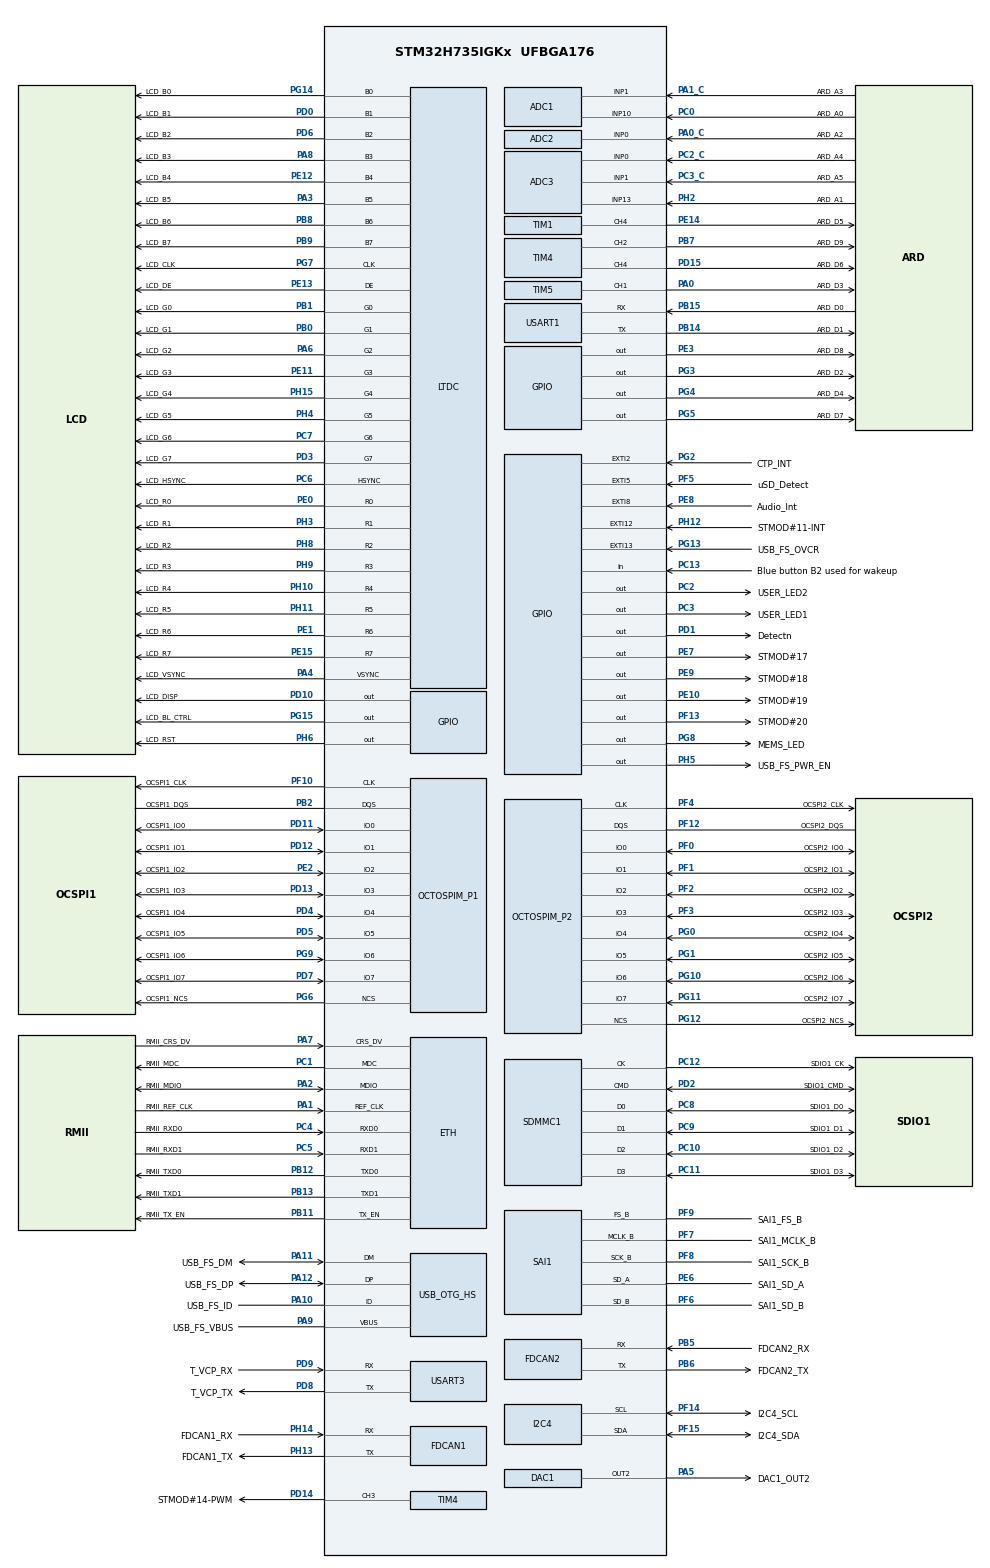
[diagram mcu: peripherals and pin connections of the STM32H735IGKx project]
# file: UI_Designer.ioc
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ADC1.Channel-1\#ChannelRegularConversion=ADC_CHANNEL_1
ADC1.NbrOfConversionFlag=1
ADC1.OffsetNumber-1\#ChannelRegularConversion=ADC_OFFSET_NONE
ADC1.OffsetSignedSaturation-1\#ChannelRegularConversion=DISABLE
ADC1.Rank-1\#ChannelRegularConversion=1
ADC1.SamplingTime-1\#ChannelRegularConversion=ADC_SAMPLETIME_1CYCLE_5
ADC1.master=1
ADC2.Channel-0\#ChannelRegularConversion=ADC_CHANNEL_0
ADC2.NbrOfConversionFlag=1
ADC2.OffsetNumber-0\#ChannelRegularConversion=ADC_OFFSET_NONE
ADC2.OffsetSignedSaturation-0\#ChannelRegularConversion=DISABLE
ADC2.Rank-0\#ChannelRegularConversion=1
ADC2.SamplingTime-0\#ChannelRegularConversion=ADC_SAMPLETIME_1CYCLE_5
ADC3.Channel-2\#ChannelRegularConversion=ADC_CHANNEL_0
ADC3.NbrOfConversionFlag=1
ADC3.OffsetNumber-2\#ChannelRegularConversion=ADC_OFFSET_NONE
ADC3.OffsetSaturation-2\#ChannelRegularConversion=DISABLE
ADC3.OffsetSign-2\#ChannelRegularConversion=ADC3_OFFSET_SIGN_NEGATIVE
ADC3.OffsetSignedSaturation-2\#ChannelRegularConversion=DISABLE
ADC3.Rank-2\#ChannelRegularConversion=1
ADC3.SamplingTime-2\#ChannelRegularConversion=ADC3_SAMPLETIME_2CYCLES_5
DAC1.DAC_Channel-DAC_OUT2=DAC_CHANNEL_2
ETH.MediaInterface=HAL_ETH_RMII_MODE
FDCAN1.CalculateBaudRateNominal=2864583
FDCAN1.CalculateTimeBitNominal=349
FDCAN1.CalculateTimeQuantumNominal=116.36363636363636
FDCAN2.CalculateBaudRateNominal=2864583
FDCAN2.CalculateTimeBitNominal=349
FDCAN2.CalculateTimeQuantumNominal=116.36363636363636
I2C4.Timing=0x60404E72
Mcu.Family=STM32H7
Mcu.Name=STM32H735IGKx
Mcu.Package=UFBGA176
NVIC.PriorityGroup=NVIC_PRIORITYGROUP_4
PA0.GPIO_Label=ARD_D3
PA0.Signal=S_TIM5_CH1
PA0_C.GPIO_Label=ARD_A2
PA0_C.Signal=ADCx_INP0
PA1.GPIO_Label=RMII_REF_CLK
PA1.GPIO_Speed=GPIO_SPEED_FREQ_LOW
PA1.Mode=RMII
PA1.Signal=ETH_REF_CLK
PA10.GPIO_Label=USB_FS_ID
PA10.Mode=OTG/Dual-Role-Device-FS
PA10.Signal=USB_OTG_HS_ID
PA11.GPIO_Label=USB_FS_DM
PA11.Mode=OTG/Dual-Role-Device-FS
PA11.Signal=USB_OTG_HS_DM
PA12.GPIO_Label=USB_FS_DP
PA12.Mode=OTG/Dual-Role-Device-FS
PA12.Signal=USB_OTG_HS_DP
PA13(JTMS/SWDIO).GPIO_Label=JTMS
PA13(JTMS/SWDIO).Mode=Trace_Asynchronous_SW
PA13(JTMS/SWDIO).Signal=DEBUG_JTMS-SWDIO
PA14(JTCK/SWCLK).GPIO_Label=JTCK
PA14(JTCK/SWCLK).Mode=Trace_Asynchronous_SW
PA14(JTCK/SWCLK).Signal=DEBUG_JTCK-SWCLK
PA15(JTDI).GPIO_Label=JTDI
PA15(JTDI).Signal=DEBUG_JTDI
PA1_C.GPIO_Label=ARD_A3
PA1_C.Signal=ADCx_INP1
PA2.GPIO_Label=RMII_MDIO
PA2.GPIO_Speed=GPIO_SPEED_FREQ_LOW
PA2.Mode=RMII
PA2.Signal=ETH_MDIO
PA3.GPIO_Label=LCD_B5
PA3.GPIO_Speed=GPIO_SPEED_FREQ_LOW
PA3.Mode=RGB888
PA3.Signal=LTDC_B5
PA4.GPIO_Label=LCD_VSYNC
PA4.GPIO_Speed=GPIO_SPEED_FREQ_LOW
PA4.Mode=RGB888
PA4.Signal=LTDC_VSYNC
PA5.GPIO_Label=DAC1_OUT2
PA5.Signal=COMP_DAC12_group
PA6.GPIO_Label=LCD_G2
PA6.GPIO_Speed=GPIO_SPEED_FREQ_LOW
PA6.Mode=RGB888
PA6.Signal=LTDC_G2
PA7.GPIO_Label=RMII_CRS_DV
PA7.GPIO_Speed=GPIO_SPEED_FREQ_LOW
PA7.Mode=RMII
PA7.Signal=ETH_CRS_DV
PA8.GPIO_Label=LCD_B3
PA8.GPIO_Speed=GPIO_SPEED_FREQ_LOW
PA8.Mode=RGB888
PA8.Signal=LTDC_B3
PA9.GPIO_Label=USB_FS_VBUS
PA9.Mode=Activate_VBUS_FS
PA9.Signal=USB_OTG_HS_VBUS
PB0.GPIO_Label=LCD_G1
PB0.GPIO_Speed=GPIO_SPEED_FREQ_LOW
PB0.Mode=RGB888
PB0.Signal=LTDC_G1
PB1.GPIO_Label=LCD_G0
PB1.GPIO_Speed=GPIO_SPEED_FREQ_LOW
PB1.Mode=RGB888
PB1.Signal=LTDC_G0
PB10.GPIO_Label=RMII_RX_ER
PB10.Signal=ETH_RX_ER
PB11.GPIO_Label=RMII_TX_EN
PB11.GPIO_Speed=GPIO_SPEED_FREQ_LOW
PB11.Mode=RMII
PB11.Signal=ETH_TX_EN
PB12.GPIO_Label=RMII_TXD0
PB12.GPIO_Speed=GPIO_SPEED_FREQ_LOW
PB12.Mode=RMII
PB12.Signal=ETH_TXD0
PB13.GPIO_Label=RMII_TXD1
PB13.GPIO_Speed=GPIO_SPEED_FREQ_LOW
PB13.Mode=RMII
PB13.Signal=ETH_TXD1
PB14.GPIO_Label=ARD_D1
PB14.GPIO_PuPd=GPIO_NOPULL
PB14.Mode=Asynchronous
PB14.Signal=USART1_TX
PB15.GPIO_Label=ARD_D0
PB15.GPIO_PuPd=GPIO_NOPULL
PB15.Mode=Asynchronous
PB15.Signal=USART1_RX
PB2.GPIO_Label=OCSPI1_DQS
PB2.Mode=OCTOSPI1_Port1_DQS
PB2.Signal=OCTOSPIM_P1_DQS
PB3(JTDO/TRACESWO).GPIO_Label=JTDO
PB3(JTDO/TRACESWO).Mode=Trace_Asynchronous_SW
PB3(JTDO/TRACESWO).Signal=DEBUG_JTDO-SWO
PB4(NJTRST).GPIO_Label=NJTRST
PB4(NJTRST).Signal=DEBUG_JTRST
PB5.GPIO_Label=FDCAN2_RX
PB5.Mode=FDCAN_Activate
PB5.Signal=FDCAN2_RX
PB6.GPIO_Label=FDCAN2_TX
PB6.Mode=FDCAN_Activate
PB6.Signal=FDCAN2_TX
PB7.GPIO_Label=ARD_D9
PB7.Signal=S_TIM4_CH2
PB8.GPIO_Label=LCD_B6
PB8.GPIO_Speed=GPIO_SPEED_FREQ_LOW
PB8.Mode=RGB888
PB8.Signal=LTDC_B6
PB9.GPIO_Label=LCD_B7
PB9.GPIO_Speed=GPIO_SPEED_FREQ_LOW
PB9.Mode=RGB888
PB9.Signal=LTDC_B7
PC0.GPIO_Label=ARD_A0
PC0.Signal=ADCx_INP10
PC1.GPIO_Label=RMII_MDC
PC1.GPIO_Speed=GPIO_SPEED_FREQ_LOW
PC1.Mode=RMII
PC1.Signal=ETH_MDC
PC10.GPIO_Label=SDIO1_D2
PC10.Mode=SD_4_bits_Wide_bus
PC10.Signal=SDMMC1_D2
PC11.GPIO_Label=SDIO1_D3
PC11.Mode=SD_4_bits_Wide_bus
PC11.Signal=SDMMC1_D3
PC12.GPIO_Label=SDIO1_CK
PC12.Mode=SD_4_bits_Wide_bus
PC12.Signal=SDMMC1_CK
PC13.GPIO_Label=Blue button B2 used for wakeup
PC13.Signal=GPIO_Input
PC14-OSC32_IN.Mode=LSE-External-Oscillator
PC14-OSC32_IN.Signal=RCC_OSC32_IN
PC15-OSC32_OUT.Mode=LSE-External-Oscillator
PC15-OSC32_OUT.Signal=RCC_OSC32_OUT
PC2.GPIO_Label=USER_LED2
PC2.Signal=GPIO_Output
PC2_C.GPIO_Label=ARD_A4
PC2_C.Mode=IN0-Single-Ended
PC2_C.Signal=ADC3_INP0
PC3.GPIO_Label=USER_LED1
PC3.Signal=GPIO_Output
PC3_C.GPIO_Label=ARD_A5
PC3_C.Mode=IN1-Single-Ended
PC3_C.Signal=ADC3_INP1
PC4.GPIO_Label=RMII_RXD0
PC4.GPIO_Speed=GPIO_SPEED_FREQ_LOW
PC4.Mode=RMII
PC4.Signal=ETH_RXD0
PC5.GPIO_Label=RMII_RXD1
PC5.GPIO_Speed=GPIO_SPEED_FREQ_LOW
PC5.Mode=RMII
PC5.Signal=ETH_RXD1
PC6.GPIO_Label=LCD_HSYNC
PC6.GPIO_Speed=GPIO_SPEED_FREQ_LOW
PC6.Mode=RGB888
PC6.Signal=LTDC_HSYNC
PC7.GPIO_Label=LCD_G6
PC7.GPIO_Speed=GPIO_SPEED_FREQ_LOW
PC7.Mode=RGB888
PC7.Signal=LTDC_G6
PC8.GPIO_Label=SDIO1_D0
PC8.Mode=SD_4_bits_Wide_bus
PC8.Signal=SDMMC1_D0
PC9.GPIO_Label=SDIO1_D1
PC9.Mode=SD_4_bits_Wide_bus
PC9.Signal=SDMMC1_D1
PD0.GPIO_Label=LCD_B1
PD0.GPIO_Speed=GPIO_SPEED_FREQ_LOW
PD0.Mode=RGB888
PD0.Signal=LTDC_B1
PD1.GPIO_Label=Detectn
PD1.GPIO_PuPd=GPIO_NOPULL
PD1.Signal=GPIO_Output
PD10.GPIO_Label=LCD_DISP
PD10.GPIO_Speed=GPIO_SPEED_FREQ_LOW
PD10.Signal=GPIO_Output
PD11.GPIO_Label=OCSPI1_IO0
PD11.Mode=OCTOSPI1_IOL_Port1L
PD11.Signal=OCTOSPIM_P1_IO0
PD12.GPIO_Label=OCSPI1_IO1
PD12.Mode=OCTOSPI1_IOL_Port1L
PD12.Signal=OCTOSPIM_P1_IO1
PD13.GPIO_Label=OCSPI1_IO3
PD13.Mode=OCTOSPI1_IOL_Port1L
PD13.Signal=OCTOSPIM_P1_IO3
PD14.GPIO_Label=STMOD\#14-PWM
PD14.Signal=S_TIM4_CH3
PD15.GPIO_Label=ARD_D6
PD15.Signal=S_TIM4_CH4
PD2.GPIO_Label=SDIO1_CMD
PD2.Mode=SD_4_bits_Wide_bus
PD2.Signal=SDMMC1_CMD
PD3.GPIO_Label=LCD_G7
PD3.GPIO_Speed=GPIO_SPEED_FREQ_LOW
PD3.Mode=RGB888
PD3.Signal=LTDC_G7
PD4.GPIO_Label=OCSPI1_IO4
PD4.Mode=OCTOSPI1_IOH_Port1H
PD4.Signal=OCTOSPIM_P1_IO4
PD5.GPIO_Label=OCSPI1_IO5
PD5.Mode=OCTOSPI1_IOH_Port1H
PD5.Signal=OCTOSPIM_P1_IO5
PD6.GPIO_Label=LCD_B2
PD6.GPIO_Speed=GPIO_SPEED_FREQ_LOW
PD6.Mode=RGB888
PD6.Signal=LTDC_B2
PD7.GPIO_Label=OCSPI1_IO7
PD7.Mode=OCTOSPI1_IOH_Port1H
PD7.Signal=OCTOSPIM_P1_IO7
PD8.GPIO_Label=T_VCP_TX
PD8.GPIO_PuPd=GPIO_NOPULL
PD8.Mode=Asynchronous
PD8.Signal=USART3_TX
PD9.GPIO_Label=T_VCP_RX
PD9.GPIO_PuPd=GPIO_NOPULL
PD9.Mode=Asynchronous
PD9.Signal=USART3_RX
PE0.GPIO_Label=LCD_R0
PE0.GPIO_Speed=GPIO_SPEED_FREQ_LOW
PE0.Mode=RGB888
PE0.Signal=LTDC_R0
PE1.GPIO_Label=LCD_R6
PE1.GPIO_Speed=GPIO_SPEED_FREQ_LOW
PE1.Mode=RGB888
PE1.Signal=LTDC_R6
PE10.GPIO_Label=STMOD\#19
PE10.Signal=GPIO_Output
PE11.GPIO_Label=LCD_G3
PE11.GPIO_Speed=GPIO_SPEED_FREQ_LOW
PE11.Mode=RGB888
PE11.Signal=LTDC_G3
PE12.GPIO_Label=LCD_B4
PE12.GPIO_Speed=GPIO_SPEED_FREQ_LOW
PE12.Mode=RGB888
PE12.Signal=LTDC_B4
PE13.GPIO_Label=LCD_DE
PE13.GPIO_Speed=GPIO_SPEED_FREQ_LOW
PE13.Mode=RGB888
PE13.Signal=LTDC_DE
PE14.GPIO_Label=ARD_D5
PE14.Signal=S_TIM1_CH4
PE15.GPIO_Label=LCD_R7
PE15.GPIO_Speed=GPIO_SPEED_FREQ_LOW
PE15.Mode=RGB888
PE15.Signal=LTDC_R7
PE2.GPIO_Label=OCSPI1_IO2
PE2.Mode=OCTOSPI1_IOL_Port1L
PE2.Signal=OCTOSPIM_P1_IO2
PE3.GPIO_Label=ARD_D8
PE3.Signal=GPIO_Output
PE4.GPIO_Label=SAI4_D2
PE4.Signal=SAI4_D2
PE5.GPIO_Label=SAI4_CK2
PE5.Signal=SAI4_CK2
PE6.GPIO_Label=SAI1_SD_A
PE6.Mode=SAI_A_SyncSlave
PE6.Signal=SAI1_SD_A
PE7.GPIO_Label=STMOD\#17
PE7.Signal=GPIO_Output
PE8.GPIO_Label=Audio_Int
PE8.Signal=GPXTI8
PE9.GPIO_Label=STMOD\#18
PE9.Signal=GPIO_Output
PF0.GPIO_Label=OCSPI2_IO0
PF0.Mode=OCTOSPI2_IOL_Port2L
PF0.Signal=OCTOSPIM_P2_IO0
PF1.GPIO_Label=OCSPI2_IO1
PF1.Mode=OCTOSPI2_IOL_Port2L
PF1.Signal=OCTOSPIM_P2_IO1
PF10.GPIO_Label=OCSPI1_CLK
PF10.Mode=O1_P1_CLK
PF10.Signal=OCTOSPIM_P1_CLK
PF11.GPIO_Label=SPI5_MOSI
PF11.Signal=SPI5_MOSI
PF12.GPIO_Label=OCSPI2_DQS
PF12.Mode=OCTOSPI2_Port2_DQS
PF12.Signal=OCTOSPIM_P2_DQS
PF13.GPIO_Label=STMOD\#20
PF13.Signal=GPIO_Output
PF14.GPIO_Label=I2C4_SCL
PF14.GPIO_Pu=GPIO_PULLUP
PF14.Mode=I2C
PF14.Signal=I2C4_SCL
PF15.GPIO_Label=I2C4_SDA
PF15.GPIO_Pu=GPIO_PULLUP
PF15.Mode=I2C
PF15.Signal=I2C4_SDA
PF2.GPIO_Label=OCSPI2_IO2
PF2.Mode=OCTOSPI2_IOL_Port2L
PF2.Signal=OCTOSPIM_P2_IO2
PF3.GPIO_Label=OCSPI2_IO3
PF3.Mode=OCTOSPI2_IOL_Port2L
PF3.Signal=OCTOSPIM_P2_IO3
PF4.GPIO_Label=OCSPI2_CLK
PF4.Mode=O2_P2_CLK
PF4.Signal=OCTOSPIM_P2_CLK
PF5.GPIO_Label=uSD_Detect
PF5.Signal=GPXTI5
PF6.GPIO_Label=SAI1_SD_B
PF6.Mode=SAI_B_MasterWithClock
PF6.Signal=SAI1_SD_B
PF7.GPIO_Label=SAI1_MCLK_B
PF7.Mode=SAI_B_MasterWithClock
PF7.Signal=SAI1_MCLK_B
PF8.GPIO_Label=SAI1_SCK_B
PF8.Mode=SAI_B_MasterWithClock
PF8.Signal=SAI1_SCK_B
PF9.GPIO_Label=SAI1_FS_B
PF9.Mode=SAI_B_MasterWithClock
PF9.Signal=SAI1_FS_B
PG0.GPIO_Label=OCSPI2_IO4
PG0.Mode=OCTOSPI2_IOH_Port2H
PG0.Signal=OCTOSPIM_P2_IO4
PG1.GPIO_Label=OCSPI2_IO5
PG1.Mode=OCTOSPI2_IOH_Port2H
PG1.Signal=OCTOSPIM_P2_IO5
PG10.GPIO_Label=OCSPI2_IO6
PG10.Mode=OCTOSPI2_IOH_Port2H
PG10.Signal=OCTOSPIM_P2_IO6
PG11.GPIO_Label=OCSPI2_IO7
PG11.Mode=OCTOSPI2_IOH_Port2H
PG11.Signal=OCTOSPIM_P2_IO7
PG12.GPIO_Label=OCSPI2_NCS
PG12.Mode=OCTOSPI2_Port2_NCS
PG12.Signal=OCTOSPIM_P2_NCS
PG13.GPIO_Label=USB_FS_OVCR
PG13.Signal=GPXTI13
PG14.GPIO_Label=LCD_B0
PG14.GPIO_Speed=GPIO_SPEED_FREQ_LOW
PG14.Mode=RGB888
PG14.Signal=LTDC_B0
PG15.GPIO_Label=LCD_BL_CTRL
PG15.GPIO_Speed=GPIO_SPEED_FREQ_LOW
PG15.Signal=GPIO_Output
PG2.GPIO_Label=CTP_INT
PG2.Signal=GPXTI2
PG3.GPIO_Label=ARD_D2
PG3.Signal=GPIO_Output
PG4.GPIO_Label=ARD_D4
PG4.Signal=GPIO_Output
PG5.GPIO_Label=ARD_D7
PG5.Signal=GPIO_Output
PG6.GPIO_Label=OCSPI1_NCS
PG6.Mode=OCTOSPI1_Port1_NCS
PG6.Signal=OCTOSPIM_P1_NCS
PG7.GPIO_Label=LCD_CLK
PG7.GPIO_Speed=GPIO_SPEED_FREQ_LOW
PG7.Mode=RGB888
PG7.Signal=LTDC_CLK
PG8.GPIO_Label=MEMS_LED
PG8.Signal=GPIO_Output
PG9.GPIO_Label=OCSPI1_IO6
PG9.Mode=OCTOSPI1_IOH_Port1H
PG9.Signal=OCTOSPIM_P1_IO6
PH0-OSC_IN.Mode=HSE-External-Oscillator
PH0-OSC_IN.Signal=RCC_OSC_IN
PH1-OSC_OUT.Mode=HSE-External-Oscillator
PH1-OSC_OUT.Signal=RCC_OSC_OUT
PH10.GPIO_Label=LCD_R4
PH10.GPIO_Speed=GPIO_SPEED_FREQ_LOW
PH10.Mode=RGB888
PH10.Signal=LTDC_R4
PH11.GPIO_Label=LCD_R5
PH11.GPIO_Speed=GPIO_SPEED_FREQ_LOW
PH11.Mode=RGB888
PH11.Signal=LTDC_R5
PH12.GPIO_Label=STMOD\#11-INT
PH12.Signal=GPXTI12
PH13.GPIO_Label=FDCAN1_TX
PH13.Mode=FDCAN_Activate
PH13.Signal=FDCAN1_TX
PH14.GPIO_Label=FDCAN1_RX
PH14.Mode=FDCAN_Activate
PH14.Signal=FDCAN1_RX
PH15.GPIO_Label=LCD_G4
PH15.GPIO_Speed=GPIO_SPEED_FREQ_LOW
PH15.Mode=RGB888
PH15.Signal=LTDC_G4
PH2.GPIO_Label=ARD_A1
PH2.Mode=IN13-Single-Ended
PH2.Signal=ADC3_INP13
PH3.GPIO_Label=LCD_R1
PH3.GPIO_Speed=GPIO_SPEED_FREQ_LOW
PH3.Mode=RGB888
PH3.Signal=LTDC_R1
PH4.GPIO_Label=LCD_G5
PH4.GPIO_Speed=GPIO_SPEED_FREQ_LOW
PH4.Mode=RGB888
PH4.Signal=LTDC_G5
PH5.GPIO_Label=USB_FS_PWR_EN
PH5.Signal=GPIO_Output
PH6.GPIO_Label=LCD_RST
PH6.GPIO_Speed=GPIO_SPEED_FREQ_LOW
PH6.Signal=GPIO_Output
PH7.GPIO_Label=SPI5_MISO
PH7.Signal=SPI5_MISO
PH8.GPIO_Label=LCD_R2
PH8.GPIO_Speed=GPIO_SPEED_FREQ_LOW
PH8.Mode=RGB888
PH8.Signal=LTDC_R2
PH9.GPIO_Label=LCD_R3
PH9.GPIO_Speed=GPIO_SPEED_FREQ_LOW
PH9.Mode=RGB888
PH9.Signal=LTDC_R3
ProjectManager.HeapSize=0x200
ProjectManager.StackSize=0x400
ProjectManager.TargetToolchain=STM32CubeIDE
RCC.ADCFreq_Value=80000000
RCC.APB1Freq_Value=137500000
RCC.APB2Freq_Value=137500000
RCC.APB3Freq_Value=137500000
RCC.APB4Freq_Value=137500000
RCC.CortexFreq_Value=550000000
RCC.D1PPRE=RCC_APB3_DIV2
RCC.D2PPRE1=RCC_APB1_DIV2
RCC.D2PPRE2=RCC_APB2_DIV2
RCC.D3PPRE=RCC_APB4_DIV2
RCC.DIVM1=5
RCC.DIVM2=5
RCC.DIVN1=110
RCC.DIVN2=80
RCC.DIVP1=1
RCC.DIVP2=5
RCC.DIVQ1=4
RCC.HCLKFreq_Value=275000000
RCC.HPRE=RCC_HCLK_DIV2
RCC.PLL2FRACN=0
RCC.PLL3FRACN=0
RCC.PLLFRACN=0
RCC.PLLSourceVirtual=RCC_PLLSOURCE_HSE
RCC.SYSCLKFreq_VALUE=550000000
RCC.SYSCLKSource=RCC_SYSCLKSOURCE_PLLCLK
RCC.USBCLockSelection=RCC_USBCLKSOURCE_HSI48
RCC.USBFreq_Value=48000000
SAI1.ErrorAudioFreq-SAI_B_MasterWithClock=39.87 %
SAI1.Instance-SAI_A_SyncSlave=SAI$Index_Block_A
SAI1.Instance-SAI_B_MasterWithClock=SAI$Index_Block_B
SAI1.MckOutput-SAI_B_MasterWithClock=SAI_MCK_OUTPUT_ENABLE
SAI1.RealAudioFreq-SAI_B_MasterWithClock=268.554 KHz
SAI1.VirtualMode-SAI_A_SyncSlave=VM_SLAVE
SAI1.VirtualMode-SAI_B_MasterWithClock=VM_MASTER
SH.ADCx_INP0.0=ADC1_INP0
SH.ADCx_INP0.1=ADC2_INP0,IN0-Single-Ended
SH.ADCx_INP1.0=ADC2_INP1
SH.ADCx_INP1.1=ADC1_INP1,IN1-Single-Ended
SH.ADCx_INP10.0=ADC1_INP10,IN10-Single-Ended
SH.COMP_DAC12_group.0=DAC1_OUT2,DAC_OUT2
SH.S_TIM1_CH4.0=TIM1_CH4,PWM Generation4 CH4
SH.S_TIM4_CH2.0=TIM4_CH2,PWM Generation2 CH2
SH.S_TIM4_CH3.0=TIM4_CH3,PWM Generation3 CH3
SH.S_TIM4_CH4.0=TIM4_CH4,PWM Generation4 CH4
SH.S_TIM5_CH1.0=TIM5_CH1,PWM Generation1 CH1
TIM1.Channel-PWM\ Generation4\ CH4=TIM_CHANNEL_4
TIM4.Channel-PWM\ Generation2\ CH2=TIM_CHANNEL_2
TIM4.Channel-PWM\ Generation3\ CH3=TIM_CHANNEL_3
TIM4.Channel-PWM\ Generation4\ CH4=TIM_CHANNEL_4
TIM5.Channel-PWM\ Generation1\ CH1=TIM_CHANNEL_1
USART1.VirtualMode-Asynchronous=VM_ASYNC
USART3.VirtualMode-Asynchronous=VM_ASYNC
VP_DMA2D_VS_DMA2D.Mode=DMA2D_Activate
VP_MEMORYMAP_VS_MEMORYMAP.Mode=CurAppReg
VP_OCTOSPI1_VS_octo.Mode=octo_mode
VP_OCTOSPI2_VS_octo.Mode=hyperbus_mode
board=STM32H735G-DK

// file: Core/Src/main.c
/* USER CODE BEGIN Header */
/**
  ******************************************************************************
  * @file           : main.c
  * @brief          : Main program body
  ******************************************************************************
  * @attention
  *
  * Copyright (c) 2026 STMicroelectronics.
  * All rights reserved.
  *
  * This software is licensed under terms that can be found in the LICENSE file
  * in the root directory of this software component.
  * If no LICENSE file comes with this software, it is provided AS-IS.
  *
  ******************************************************************************
  */
/* USER CODE END Header */
#include "main.h"
#include "adc.h"
#include "dac.h"
#include "dma2d.h"
#include "eth.h"
#include "fdcan.h"
#include "i2c.h"
#include "ltdc.h"
#include "octospi.h"
#include "sai.h"
#include "sdmmc.h"
#include "tim.h"
#include "usart.h"
#include "usb_otg.h"
#include "gpio.h"

void SystemClock_Config(void);
void PeriphCommonClock_Config(void);

int main(void)
{

  /* MCU Configuration--------------------------------------------------------*/

  /* Reset of all peripherals, Initializes the Flash interface and the Systick. */
  HAL_Init();

  /* Configure the system clock */
  SystemClock_Config();

  /* Configure the peripherals common clocks */
  PeriphCommonClock_Config();

  /* Initialize all configured peripherals */
  MX_GPIO_Init();
  MX_ADC1_Init();
  MX_ADC2_Init();
  MX_ADC3_Init();
  MX_DAC1_Init();
  MX_DMA2D_Init();
  MX_ETH_Init();
  MX_FDCAN1_Init();
  MX_FDCAN2_Init();
  MX_I2C4_Init();
  MX_LTDC_Init();
  MX_OCTOSPI1_Init();
  MX_OCTOSPI2_Init();
  MX_SAI1_Init();
  MX_SDMMC1_SD_Init();
  MX_TIM1_Init();
  MX_TIM4_Init();
  MX_TIM5_Init();
  MX_USART1_UART_Init();
  MX_USART3_UART_Init();
  MX_USB_OTG_HS_USB_Init();
  /* USER CODE BEGIN 2 */

  /* Initialize UI Rendering System */
  UI_FramebufferInit();
  UI_RenderInit();

  /* USER CODE END 2 */

  /* Infinite loop */
  while (1)
  {

  }
}

void SystemClock_Config(void)
{
  RCC_OscInitTypeDef RCC_OscInitStruct = {0};
  RCC_ClkInitTypeDef RCC_ClkInitStruct = {0};

  /** Supply configuration update enable
  */
  HAL_PWREx_ConfigSupply(PWR_DIRECT_SMPS_SUPPLY);

  /** Configure the main internal regulator output voltage
  */
  __HAL_PWR_VOLTAGESCALING_CONFIG(PWR_REGULATOR_VOLTAGE_SCALE0);

  while(!__HAL_PWR_GET_FLAG(PWR_FLAG_VOSRDY)) {}

  /** Initializes the RCC Oscillators according to the specified parameters
  * in the RCC_OscInitTypeDef structure.
  */
  RCC_OscInitStruct.OscillatorType = RCC_OSCILLATORTYPE_HSI48|RCC_OSCILLATORTYPE_HSE;
  RCC_OscInitStruct.HSEState = RCC_HSE_ON;
  RCC_OscInitStruct.HSI48State = RCC_HSI48_ON;
  RCC_OscInitStruct.PLL.PLLState = RCC_PLL_ON;
  RCC_OscInitStruct.PLL.PLLSource = RCC_PLLSOURCE_HSE;
  RCC_OscInitStruct.PLL.PLLM = 5;
  RCC_OscInitStruct.PLL.PLLN = 110;
  RCC_OscInitStruct.PLL.PLLP = 1;
  RCC_OscInitStruct.PLL.PLLQ = 4;
  RCC_OscInitStruct.PLL.PLLR = 2;
  RCC_OscInitStruct.PLL.PLLRGE = RCC_PLL1VCIRANGE_2;
  RCC_OscInitStruct.PLL.PLLVCOSEL = RCC_PLL1VCOWIDE;
  RCC_OscInitStruct.PLL.PLLFRACN = 0;
  if (HAL_RCC_OscConfig(&RCC_OscInitStruct) != HAL_OK)
  {
    Error_Handler();
  }

  /** Initializes the CPU, AHB and APB buses clocks
  */
  RCC_ClkInitStruct.ClockType = RCC_CLOCKTYPE_HCLK|RCC_CLOCKTYPE_SYSCLK
                              |RCC_CLOCKTYPE_PCLK1|RCC_CLOCKTYPE_PCLK2
                              |RCC_CLOCKTYPE_D3PCLK1|RCC_CLOCKTYPE_D1PCLK1;
  RCC_ClkInitStruct.SYSCLKSource = RCC_SYSCLKSOURCE_PLLCLK;
  RCC_ClkInitStruct.SYSCLKDivider = RCC_SYSCLK_DIV1;
  RCC_ClkInitStruct.AHBCLKDivider = RCC_HCLK_DIV2;
  RCC_ClkInitStruct.APB3CLKDivider = RCC_APB3_DIV2;
  RCC_ClkInitStruct.APB1CLKDivider = RCC_APB1_DIV2;
  RCC_ClkInitStruct.APB2CLKDivider = RCC_APB2_DIV2;
  RCC_ClkInitStruct.APB4CLKDivider = RCC_APB4_DIV2;

  if (HAL_RCC_ClockConfig(&RCC_ClkInitStruct, FLASH_LATENCY_3) != HAL_OK)
  {
    Error_Handler();
  }
}

void PeriphCommonClock_Config(void)
{
  RCC_PeriphCLKInitTypeDef PeriphClkInitStruct = {0};

  /** Initializes the peripherals clock
  */
  PeriphClkInitStruct.PeriphClockSelection = RCC_PERIPHCLK_ADC;
  PeriphClkInitStruct.PLL2.PLL2M = 5;
  PeriphClkInitStruct.PLL2.PLL2N = 80;
  PeriphClkInitStruct.PLL2.PLL2P = 5;
  PeriphClkInitStruct.PLL2.PLL2Q = 2;
  PeriphClkInitStruct.PLL2.PLL2R = 2;
  PeriphClkInitStruct.PLL2.PLL2RGE = RCC_PLL2VCIRANGE_2;
  PeriphClkInitStruct.PLL2.PLL2VCOSEL = RCC_PLL2VCOWIDE;
  PeriphClkInitStruct.PLL2.PLL2FRACN = 0;
  PeriphClkInitStruct.AdcClockSelection = RCC_ADCCLKSOURCE_PLL2;
  if (HAL_RCCEx_PeriphCLKConfig(&PeriphClkInitStruct) != HAL_OK)
  {
    Error_Handler();
  }
}

void Error_Handler(void)
{
  __disable_irq();
  while (1)
  {
  }
}
